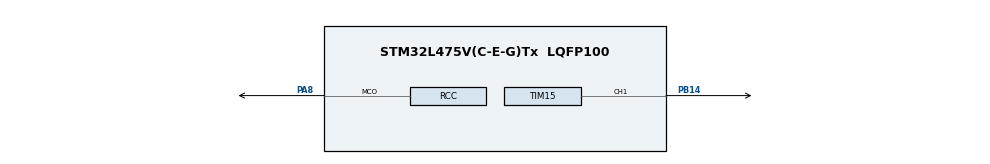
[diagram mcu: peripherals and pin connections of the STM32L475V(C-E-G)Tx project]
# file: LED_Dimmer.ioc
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Mcu.Family=STM32L4
Mcu.Name=STM32L475V(C-E-G)Tx
Mcu.Package=LQFP100
NVIC.PriorityGroup=NVIC_PRIORITYGROUP_4
PA8.Mode=Clock-out
PA8.Signal=RCC_MCO
PB14.Signal=S_TIM15_CH1
PH0-OSC_IN\ (PH0).Mode=HSE-External-Oscillator
PH0-OSC_IN\ (PH0).Signal=RCC_OSC_IN
PH1-OSC_OUT\ (PH1).Mode=HSE-External-Oscillator
PH1-OSC_OUT\ (PH1).Signal=RCC_OSC_OUT
ProjectManager.HeapSize=0x200
ProjectManager.StackSize=0x400
ProjectManager.TargetToolchain=EWARM V8.32
RCC.HSE_VALUE=8000000
RCC.HSI_VALUE=16000000
RCC.LSE_VALUE=32768
RCC.MSI_VALUE=4000000
RCC.VCOOutputFreq_Value=32000000
SH.S_TIM15_CH1.0=TIM15_CH1,PWM Generation1 CH1
TIM15.AutoReloadPreload=TIM_AUTORELOAD_PRELOAD_ENABLE
TIM15.Channel-PWM\ Generation1\ CH1=TIM_CHANNEL_1
VP_TIM15_VS_ClockSourceINT.Mode=Internal
board=custom

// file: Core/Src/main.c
/* USER CODE BEGIN Header */
/**
  ******************************************************************************
  * @file           : main.c
  * @brief          : Main program body
  ******************************************************************************
  * @attention
  *
  * <h2><center>&copy; Copyright (c) 2021 STMicroelectronics.
  * All rights reserved.</center></h2>
  *
  * This software component is licensed by ST under BSD 3-Clause license,
  * the "License"; You may not use this file except in compliance with the
  * License. You may obtain a copy of the License at:
  *                        opensource.org/licenses/BSD-3-Clause
  *
  ******************************************************************************
  */
/* USER CODE END Header */
#include "main.h"

TIM_HandleTypeDef htim15;

void SystemClock_Config(void);
static void MX_GPIO_Init(void);
static void MX_TIM15_Init(void);

int main(void)
{

  /* MCU Configuration--------------------------------------------------------*/

  /* Reset of all peripherals, Initializes the Flash interface and the Systick. */
  HAL_Init();

  /* Configure the system clock */
  SystemClock_Config();

  /* Initialize all configured peripherals */
  MX_GPIO_Init();
  MX_TIM15_Init();
  /* USER CODE BEGIN 2 */
  HAL_TIM_PWM_Start(&htim15, TIM_CHANNEL_1);

 // uint32_t DC = 0;

  /* USER CODE END 2 */

  /* Infinite loop */
  /* USER CODE BEGIN WHILE */
  while (1)
  {
    for(int i = 0; i<65535;i += 10)
    {
      TIM15->CCR1 = i;          //set the CCR to i and increase it by 10 until it reaches max value of PWM
    }
    for(int i = 65535; i > 1; i -= 10)
    {
      TIM15->CCR1 = i;          //lower CCR back down
    }
    /* USER CODE END WHILE */

  }
}

void SystemClock_Config(void)
{
  RCC_OscInitTypeDef RCC_OscInitStruct = {0};
  RCC_ClkInitTypeDef RCC_ClkInitStruct = {0};

  /** Configure the main internal regulator output voltage
  */
  if (HAL_PWREx_ControlVoltageScaling(PWR_REGULATOR_VOLTAGE_SCALE1) != HAL_OK)
  {
    Error_Handler();
  }
  /** Initializes the RCC Oscillators according to the specified parameters
  * in the RCC_OscInitTypeDef structure.
  */
  RCC_OscInitStruct.OscillatorType = RCC_OSCILLATORTYPE_MSI;
  RCC_OscInitStruct.MSIState = RCC_MSI_ON;
  RCC_OscInitStruct.MSICalibrationValue = 0;
  RCC_OscInitStruct.MSIClockRange = RCC_MSIRANGE_6;
  RCC_OscInitStruct.PLL.PLLState = RCC_PLL_NONE;
  if (HAL_RCC_OscConfig(&RCC_OscInitStruct) != HAL_OK)
  {
    Error_Handler();
  }
  /** Initializes the CPU, AHB and APB buses clocks
  */
  RCC_ClkInitStruct.ClockType = RCC_CLOCKTYPE_HCLK|RCC_CLOCKTYPE_SYSCLK
                              |RCC_CLOCKTYPE_PCLK1|RCC_CLOCKTYPE_PCLK2;
  RCC_ClkInitStruct.SYSCLKSource = RCC_SYSCLKSOURCE_MSI;
  RCC_ClkInitStruct.AHBCLKDivider = RCC_SYSCLK_DIV1;
  RCC_ClkInitStruct.APB1CLKDivider = RCC_HCLK_DIV1;
  RCC_ClkInitStruct.APB2CLKDivider = RCC_HCLK_DIV1;

  if (HAL_RCC_ClockConfig(&RCC_ClkInitStruct, FLASH_LATENCY_0) != HAL_OK)
  {
    Error_Handler();
  }
  HAL_RCC_MCOConfig(RCC_MCO1, RCC_MCO1SOURCE_SYSCLK, RCC_MCODIV_1);
}

static void MX_TIM15_Init(void)
{

  TIM_ClockConfigTypeDef sClockSourceConfig = {0};
  TIM_MasterConfigTypeDef sMasterConfig = {0};
  TIM_OC_InitTypeDef sConfigOC = {0};
  TIM_BreakDeadTimeConfigTypeDef sBreakDeadTimeConfig = {0};

  htim15.Instance = TIM15;
  htim15.Init.Prescaler = 0;
  htim15.Init.CounterMode = TIM_COUNTERMODE_UP;
  htim15.Init.Period = 65535;
  htim15.Init.ClockDivision = TIM_CLOCKDIVISION_DIV1;
  htim15.Init.RepetitionCounter = 0;
  htim15.Init.AutoReloadPreload = TIM_AUTORELOAD_PRELOAD_ENABLE;
  if (HAL_TIM_Base_Init(&htim15) != HAL_OK)
  {
    Error_Handler();
  }
  sClockSourceConfig.ClockSource = TIM_CLOCKSOURCE_INTERNAL;
  if (HAL_TIM_ConfigClockSource(&htim15, &sClockSourceConfig) != HAL_OK)
  {
    Error_Handler();
  }
  if (HAL_TIM_PWM_Init(&htim15) != HAL_OK)
  {
    Error_Handler();
  }
  sMasterConfig.MasterOutputTrigger = TIM_TRGO_RESET;
  sMasterConfig.MasterSlaveMode = TIM_MASTERSLAVEMODE_DISABLE;
  if (HAL_TIMEx_MasterConfigSynchronization(&htim15, &sMasterConfig) != HAL_OK)
  {
    Error_Handler();
  }
  sConfigOC.OCMode = TIM_OCMODE_PWM1;
  sConfigOC.Pulse = 0;
  sConfigOC.OCPolarity = TIM_OCPOLARITY_HIGH;
  sConfigOC.OCNPolarity = TIM_OCNPOLARITY_HIGH;
  sConfigOC.OCFastMode = TIM_OCFAST_DISABLE;
  sConfigOC.OCIdleState = TIM_OCIDLESTATE_RESET;
  sConfigOC.OCNIdleState = TIM_OCNIDLESTATE_RESET;
  if (HAL_TIM_PWM_ConfigChannel(&htim15, &sConfigOC, TIM_CHANNEL_1) != HAL_OK)
  {
    Error_Handler();
  }
  sBreakDeadTimeConfig.OffStateRunMode = TIM_OSSR_DISABLE;
  sBreakDeadTimeConfig.OffStateIDLEMode = TIM_OSSI_DISABLE;
  sBreakDeadTimeConfig.LockLevel = TIM_LOCKLEVEL_OFF;
  sBreakDeadTimeConfig.DeadTime = 0;
  sBreakDeadTimeConfig.BreakState = TIM_BREAK_DISABLE;
  sBreakDeadTimeConfig.BreakPolarity = TIM_BREAKPOLARITY_HIGH;
  sBreakDeadTimeConfig.AutomaticOutput = TIM_AUTOMATICOUTPUT_DISABLE;
  if (HAL_TIMEx_ConfigBreakDeadTime(&htim15, &sBreakDeadTimeConfig) != HAL_OK)
  {
    Error_Handler();
  }
  HAL_TIM_MspPostInit(&htim15);

}

static void MX_GPIO_Init(void)
{
  GPIO_InitTypeDef GPIO_InitStruct = {0};

  /* GPIO Ports Clock Enable */
  __HAL_RCC_GPIOH_CLK_ENABLE();
  __HAL_RCC_GPIOB_CLK_ENABLE();
  __HAL_RCC_GPIOA_CLK_ENABLE();

  /*Configure GPIO pin : PA8 */
  GPIO_InitStruct.Pin = GPIO_PIN_8;
  GPIO_InitStruct.Mode = GPIO_MODE_AF_PP;
  GPIO_InitStruct.Pull = GPIO_NOPULL;
  GPIO_InitStruct.Speed = GPIO_SPEED_FREQ_LOW;
  GPIO_InitStruct.Alternate = GPIO_AF0_MCO;
  HAL_GPIO_Init(GPIOA, &GPIO_InitStruct);

}

void Error_Handler(void)
{
  __disable_irq();
  while (1)
  {
  }
}

/************************ (C) COPYRIGHT STMicroelectronics *****END OF FILE****/
